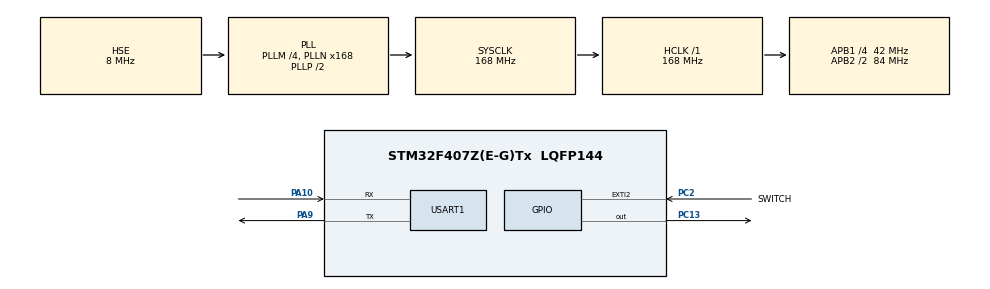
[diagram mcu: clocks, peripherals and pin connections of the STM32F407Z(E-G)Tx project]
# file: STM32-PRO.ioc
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Mcu.Family=STM32F4
Mcu.Name=STM32F407Z(E-G)Tx
Mcu.Package=LQFP144
NVIC.EXTI2_IRQn=true\:1\:0\:true\:false\:true\:true\:true\:true
NVIC.PriorityGroup=NVIC_PRIORITYGROUP_4
NVIC.USART1_IRQn=true\:0\:0\:false\:false\:true\:true\:true\:true
PA0-WKUP.Mode=SYS_WakeUp0
PA0-WKUP.Signal=SYS_WKUP
PA10.Mode=Asynchronous
PA10.Signal=USART1_RX
PA13.Mode=Serial_Wire
PA13.Signal=SYS_JTMS-SWDIO
PA14.Mode=Serial_Wire
PA14.Signal=SYS_JTCK-SWCLK
PA9.Mode=Asynchronous
PA9.Signal=USART1_TX
PC13-ANTI_TAMP.PinState=GPIO_PIN_RESET
PC13-ANTI_TAMP.Signal=GPIO_Output
PC14-OSC32_IN.Mode=LSE-External-Oscillator
PC14-OSC32_IN.Signal=RCC_OSC32_IN
PC15-OSC32_OUT.Mode=LSE-External-Oscillator
PC15-OSC32_OUT.Signal=RCC_OSC32_OUT
PC2.GPIO_Label=SWITCH
PC2.GPIO_ModeDefaultEXTI=GPIO_MODE_IT_FALLING
PC2.GPIO_PuPd=GPIO_PULLUP
PC2.Signal=GPXTI2
PH0-OSC_IN.Mode=HSE-External-Oscillator
PH0-OSC_IN.Signal=RCC_OSC_IN
PH1-OSC_OUT.Mode=HSE-External-Oscillator
PH1-OSC_OUT.Signal=RCC_OSC_OUT
ProjectManager.HeapSize=0x200
ProjectManager.StackSize=0x400
ProjectManager.TargetToolchain=Makefile
RCC.48MHZClocksFreq_Value=84000000
RCC.AHBFreq_Value=168000000
RCC.APB1CLKDivider=RCC_HCLK_DIV4
RCC.APB1Freq_Value=42000000
RCC.APB1TimFreq_Value=84000000
RCC.APB2CLKDivider=RCC_HCLK_DIV2
RCC.APB2Freq_Value=84000000
RCC.APB2TimFreq_Value=168000000
RCC.CortexFreq_Value=168000000
RCC.HCLKFreq_Value=168000000
RCC.HSE_VALUE=8000000
RCC.HSI_VALUE=16000000
RCC.PLLM=4
RCC.PLLN=168
RCC.PLLSourceVirtual=RCC_PLLSOURCE_HSE
RCC.SYSCLKFreq_VALUE=168000000
RCC.SYSCLKSource=RCC_SYSCLKSOURCE_PLLCLK
RCC.VCOOutputFreq_Value=336000000
USART1.VirtualMode=VM_ASYNC
board=custom

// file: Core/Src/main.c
/* USER CODE BEGIN Header */
/**
  ******************************************************************************
  * @file           : main.c
  * @brief          : Main program body
  ******************************************************************************
  * @attention
  *
  * Copyright (c) 2023 STMicroelectronics.
  * All rights reserved.
  *
  * This software is licensed under terms that can be found in the LICENSE file
  * in the root directory of this software component.
  * If no LICENSE file comes with this software, it is provided AS-IS.
  *
  ******************************************************************************
  */
/* USER CODE END Header */
#include "main.h"
#include "key.h"

/* USER CODE BEGIN PD */
#define LED_GPIO_Port  GPIOC

#define LED_Pin  GPIO_PIN_13
/* USER CODE END PD */

UART_HandleTypeDef huart1;

/* USER CODE BEGIN PV */
GPIO_InitTypeDef  *GPIO_InitStructC;
// SPI_HandleTypeDef hspi3;
// SD_HandleTypeDef hsd;
 uint32_t flag = 0;//自定义中断标识符�??1?7?
 uint8_t rxbuf[16] = {0};
/* USER CODE END PV */

void SystemClock_Config(void);
static void MX_GPIO_Init(void);
static void MX_USART1_UART_Init(void);
void printf_str(uint8_t *Str);

/* USER CODE BEGIN 0 */
/**
  * @brief  Rx Transfer completed callbacks.
  * @param  huart  Pointer to a UART_HandleTypeDef structure that contains
  *                the configuration information for the specified UART module.
  * @retval None
  */
void HAL_UART_RxCpltCallback(UART_HandleTypeDef *huart){

   HAL_UART_Transmit_IT(&huart1,rxbuf,10);
}
/* USER CODE END 0 */

int main(void)
{

  /* MCU Configuration--------------------------------------------------------*/

  /* Reset of all peripherals, Initializes the Flash interface and the Systick. */
  HAL_Init();

  /* USER CODE BEGIN Init */
  KEY_Init();
  /* USER CODE END Init */

  /* Configure the system clock */
  SystemClock_Config();

  /* USER CODE BEGIN SysInit */
   //USART1_Init();
  /* USER CODE END SysInit */

  /* Initialize all configured peripherals */
  MX_GPIO_Init();
  MX_USART1_UART_Init();
  /* USER CODE BEGIN 2 */

  printf_str((uint8_t *)"STM32 USART Test.\r\n");
	printf_str((uint8_t *)"printf Function Test.\r\n");
  /* USER CODE END 2 */

  /* Infinite loop */
  while (1)
  {

    /* USER CODE BEGIN 3 */
    HAL_UART_Receive_IT(&huart1,rxbuf,10);
    // HAL_UART_Transmit_IT(&huart1,(uint8_t *)"Return\r\n",sizeof("Return\r\n"));
    //HAL_Delay(1000);
  }
  /* USER CODE END 3 */
}

void SystemClock_Config(void)
{
  RCC_OscInitTypeDef RCC_OscInitStruct = {0};
  RCC_ClkInitTypeDef RCC_ClkInitStruct = {0};

  /** Configure the main internal regulator output voltage
  */
  __HAL_RCC_PWR_CLK_ENABLE();
  __HAL_PWR_VOLTAGESCALING_CONFIG(PWR_REGULATOR_VOLTAGE_SCALE1);

  /** Initializes the RCC Oscillators according to the specified parameters
  * in the RCC_OscInitTypeDef structure.
  */
  RCC_OscInitStruct.OscillatorType = RCC_OSCILLATORTYPE_HSE;
  RCC_OscInitStruct.HSEState = RCC_HSE_ON;
  RCC_OscInitStruct.PLL.PLLState = RCC_PLL_ON;
  RCC_OscInitStruct.PLL.PLLSource = RCC_PLLSOURCE_HSE;
  RCC_OscInitStruct.PLL.PLLM = 4;
  RCC_OscInitStruct.PLL.PLLN = 168;
  RCC_OscInitStruct.PLL.PLLP = RCC_PLLP_DIV2;
  RCC_OscInitStruct.PLL.PLLQ = 4;
  if (HAL_RCC_OscConfig(&RCC_OscInitStruct) != HAL_OK)
  {
    Error_Handler();
  }

  /** Initializes the CPU, AHB and APB buses clocks
  */
  RCC_ClkInitStruct.ClockType = RCC_CLOCKTYPE_HCLK|RCC_CLOCKTYPE_SYSCLK
                              |RCC_CLOCKTYPE_PCLK1|RCC_CLOCKTYPE_PCLK2;
  RCC_ClkInitStruct.SYSCLKSource = RCC_SYSCLKSOURCE_PLLCLK;
  RCC_ClkInitStruct.AHBCLKDivider = RCC_SYSCLK_DIV1;
  RCC_ClkInitStruct.APB1CLKDivider = RCC_HCLK_DIV4;
  RCC_ClkInitStruct.APB2CLKDivider = RCC_HCLK_DIV2;

  if (HAL_RCC_ClockConfig(&RCC_ClkInitStruct, FLASH_LATENCY_5) != HAL_OK)
  {
    Error_Handler();
  }
}

static void MX_USART1_UART_Init(void)
{

  huart1.Instance = USART1;
  huart1.Init.BaudRate = 115200;
  huart1.Init.WordLength = UART_WORDLENGTH_8B;
  huart1.Init.StopBits = UART_STOPBITS_1;
  huart1.Init.Parity = UART_PARITY_NONE;
  huart1.Init.Mode = UART_MODE_TX_RX;
  huart1.Init.HwFlowCtl = UART_HWCONTROL_NONE;
  huart1.Init.OverSampling = UART_OVERSAMPLING_16;
  if (HAL_UART_Init(&huart1) != HAL_OK)
  {
    Error_Handler();
  }

}

static void MX_GPIO_Init(void)
{
  GPIO_InitTypeDef GPIO_InitStruct = {0};

  /* GPIO Ports Clock Enable */
  __HAL_RCC_GPIOC_CLK_ENABLE();
  __HAL_RCC_GPIOH_CLK_ENABLE();
  __HAL_RCC_GPIOA_CLK_ENABLE();

  /*Configure GPIO pin Output Level */
  HAL_GPIO_WritePin(GPIOC, GPIO_PIN_13, GPIO_PIN_RESET);

  /*Configure GPIO pin : PC13 */
  GPIO_InitStruct.Pin = GPIO_PIN_13;
  GPIO_InitStruct.Mode = GPIO_MODE_OUTPUT_PP;
  GPIO_InitStruct.Pull = GPIO_NOPULL;
  GPIO_InitStruct.Speed = GPIO_SPEED_FREQ_LOW;
  HAL_GPIO_Init(GPIOC, &GPIO_InitStruct);

  /*Configure GPIO pin : SWITCH_Pin */
  GPIO_InitStruct.Pin = SWITCH_Pin;
  GPIO_InitStruct.Mode = GPIO_MODE_IT_FALLING;
  GPIO_InitStruct.Pull = GPIO_PULLUP;
  HAL_GPIO_Init(SWITCH_GPIO_Port, &GPIO_InitStruct);

  /* EXTI interrupt init*/
  HAL_NVIC_SetPriority(EXTI2_IRQn, 1, 0);
  HAL_NVIC_EnableIRQ(EXTI2_IRQn);

}

/* USER CODE BEGIN 4 */
// /**
//   * @brief SPI3 Initialization Function
//   * @param None
//   * @retval None
//   */
// static void MX_SPI3_Init(void)
// {

//   /* USER CODE BEGIN SPI3_Init 0 */

//   /* USER CODE END SPI3_Init 0 */

//   /* USER CODE BEGIN SPI3_Init 1 */

//   /* USER CODE END SPI3_Init 1 */
//   /* SPI3 parameter configuration*/
//   hspi3.Instance = SPI3;
//   hspi3.Init.Mode = SPI_MODE_MASTER;
//   hspi3.Init.Direction = SPI_DIRECTION_2LINES;
//   hspi3.Init.DataSize = SPI_DATASIZE_8BIT;
//   hspi3.Init.CLKPolarity = SPI_POLARITY_LOW;
//   hspi3.Init.CLKPhase = SPI_PHASE_1EDGE;
//   hspi3.Init.NSS = SPI_NSS_SOFT;
//   hspi3.Init.BaudRatePrescaler = SPI_BAUDRATEPRESCALER_2;
//   hspi3.Init.FirstBit = SPI_FIRSTBIT_MSB;
//   hspi3.Init.TIMode = SPI_TIMODE_DISABLE;
//   hspi3.Init.CRCCalculation = SPI_CRCCALCULATION_DISABLE;
//   hspi3.Init.CRCPolynomial = 10;
//   if (HAL_SPI_Init(&hspi3) != HAL_OK)
//   {
//     Error_Handler();
//   }
//   /* USER CODE BEGIN SPI3_Init 2 */

//   /* USER CODE END SPI3_Init 2 */

// }

// /**
//   * @brief SDIO Initialization Function
//   * @param None
//   * @retval None
//   */
// static void MX_SDIO_SD_Init(void)
// {

//   /* USER CODE BEGIN SDIO_Init 0 */

//   /* USER CODE END SDIO_Init 0 */

//   /* USER CODE BEGIN SDIO_Init 1 */

//   /* USER CODE END SDIO_Init 1 */
//   hsd.Instance = SDIO;
//   hsd.Init.ClockEdge = SDIO_CLOCK_EDGE_RISING;
//   hsd.Init.ClockBypass = SDIO_CLOCK_BYPASS_DISABLE;
//   hsd.Init.ClockPowerSave = SDIO_CLOCK_POWER_SAVE_DISABLE;
//   hsd.Init.BusWide = SDIO_BUS_WIDE_4B;
//   hsd.Init.HardwareFlowControl = SDIO_HARDWARE_FLOW_CONTROL_DISABLE;
//   hsd.Init.ClockDiv = 0;
//   if (HAL_SD_Init(&hsd) != HAL_OK)
//   {
//     Error_Handler();
//   }
//   if (HAL_SD_ConfigWideBusOperation(&hsd, SDIO_BUS_WIDE_4B) != HAL_OK)
//   {
//     Error_Handler();
//   }
//   /* USER CODE BEGIN SDIO_Init 2 */

//   /* USER CODE END SDIO_Init 2 */

// }
/* USER CODE END 4 */

void Error_Handler(void)
{
  __disable_irq();
  while (1)
  {
  }
}

/**
  * @brief  This function is output UART Data.
  * @Param  uint8_t *
  * @retval None
  */
void printf_str(uint8_t *Str){

    //UART1
    HAL_UART_Transmit(&huart1,Str,20,0xFFFF);
}
